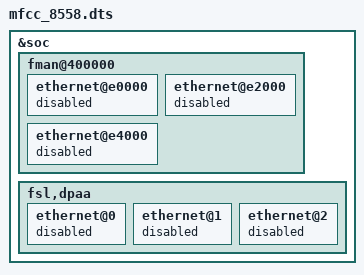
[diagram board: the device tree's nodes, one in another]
/*
 * This DTS file is for the 8558 in mission mode.  It disables the ethernet
 * devices.
 */
/include/ "mfcc-8558.dtsi"

&soc {
	fman@400000 {
		ethernet@e0000 {
			status = "disabled";
		};
		ethernet@e2000 {
			status = "disabled";
		};
		ethernet@e4000 {
			status = "disabled";
		};
	};
	fsl,dpaa {
		ethernet@0 {
			status = "disabled";
		};
		ethernet@1 {
			status = "disabled";
		};
		ethernet@2 {
			status = "disabled";
		};
	};
};
